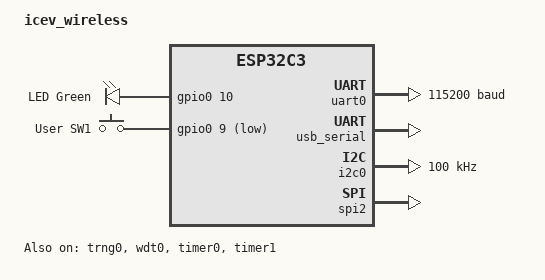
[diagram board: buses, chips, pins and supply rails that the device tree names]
/*
 * Copyright (c) 2022 Friedt Professional Engineering Services, Inc
 *
 * SPDX-License-Identifier: Apache-2.0
 */

/dts-v1/;

#include <espressif/esp32c3.dtsi>
#include "icev_wireless-pinctrl.dtsi"

/ {
	model = "icev_wireless";
	compatible = "espressif,esp32c3";

	chosen {
		zephyr,sram = &sram0;
		zephyr,console = &usb_serial;
		zephyr,shell-uart = &usb_serial;
		zephyr,flash = &flash0;
	};

	aliases {
		led0 = &led_green;
		i2c-0 = &i2c0;
		sw0 = &user_button1;
		watchdog0 = &wdt0;
	};

	leds {
		compatible = "gpio-leds";
		led_green: led_0 {
			gpios = <&gpio0 10 GPIO_ACTIVE_HIGH>;
			label = "LED Green";
		};
	};

	gpio_keys {
		compatible = "gpio-keys";
		user_button1: button_1 {
			label = "User SW1";
			gpios = <&gpio0 9 (GPIO_PULL_UP | GPIO_ACTIVE_LOW)>;
		};
	};
};

&cpu0 {
	clock-frequency = <ESP32_CLK_CPU_160M>;
};

&uart0 {
	current-speed = <115200>;
	pinctrl-0 = <&uart0_default>;
	pinctrl-names = "default";
};

&usb_serial {
	status = "okay";
};

&i2c0 {
	clock-frequency = <I2C_BITRATE_STANDARD>;
	pinctrl-0 = <&i2c0_default>;
	pinctrl-names = "default";
	status = "okay";
};

&trng0 {
	status = "okay";
};

&spi2 {
	status = "okay";
	#address-cells = <1>;
	#size-cells = <0>;
	pinctrl-0 = <&spim2_default>;
	pinctrl-names = "default";
};

&gpio0 {
	status = "okay";
};

&wdt0 {
	status = "okay";
};

&timer0 {
	status = "okay";
};

&timer1 {
	status = "okay";
};

&flash0 {
	status = "okay";
	partitions {
		compatible = "fixed-partitions";
		#address-cells = <1>;
		#size-cells = <1>;

		boot_partition: partition@0 {
			label = "mcuboot";
			reg = <0x00000000 0x0000F000>;
			read-only;
		};

		slot0_partition: partition@10000 {
			label = "image-0";
			reg = <0x00010000 0x00100000>;
		};

		slot1_partition: partition@110000 {
			label = "image-1";
			reg = <0x00110000 0x00100000>;
		};

		scratch_partition: partition@210000 {
			label = "image-scratch";
			reg = <0x00210000 0x00040000>;
		};

		storage_partition: partition@250000 {
			label = "storage";
			reg = <0x00250000 0x00006000>;
		};
	};
};
